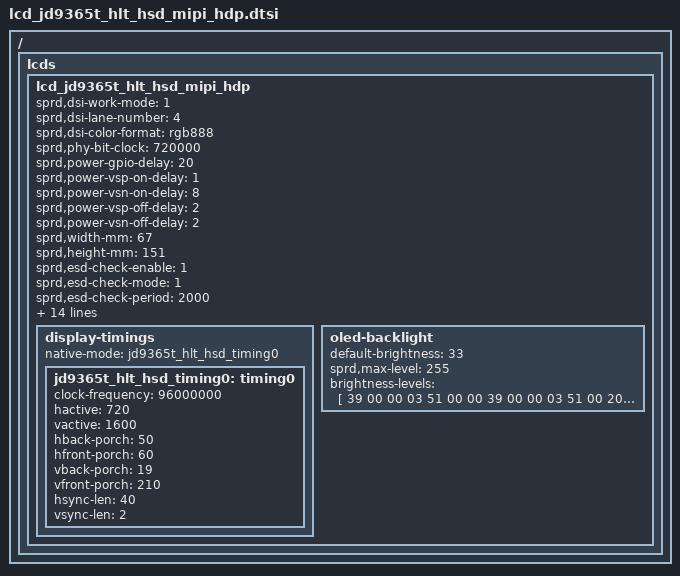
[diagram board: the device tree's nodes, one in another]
/*
 * jd9365t  LCD config dtsi file for spreadtrum
 *
 * Copyright (C) 2018, Spreadtrum Communications Inc.
 *
 * SPDX-License-Identifier: (GPL-2.0+ OR MIT)
 */

/ {
	fragment {
		target-path = "/";
		__overlay__ {
			lcds {
				lcd_jd9365t_hlt_hsd_mipi_hdp: lcd_jd9365t_hlt_hsd_mipi_hdp {
					sprd,dsi-work-mode = <1>; /* video burst mode*/
					sprd,dsi-lane-number = <4>;
					sprd,dsi-color-format = "rgb888";

					sprd,phy-bit-clock = <720000>; /* kbps */
					//sprd,phy-escape-clock = <20000>;/* kHz */
					//sprd,dpi-clk-div = <1>;
					sprd,power-gpio-delay = <20>;/* ms */
					sprd,power-vsp-on-delay = <1>;
					sprd,power-vsn-on-delay = <8>;
					sprd,power-vsp-off-delay = <2>;
					sprd,power-vsn-off-delay = <2>;

					sprd,width-mm = <67>;
					sprd,height-mm = <151>;

					sprd,esd-check-enable = <1>;
					sprd,esd-check-mode = <1>;
					sprd,esd-check-period = <2000>;

					sprd,reset-on-sequence = <1 5>, <0 10>, <1 10>;
					sprd,reset-off-sequence = <0 5>;

					sprd,ddi-need-tp-reset = <1>;
					sprd,ddi-tp-reset-gpio = <209>;

					sprd,deep-sleep-in = <1>;

					sprd,use-dcs-write;
					sprd,initial-command = [
						39 00 00 04 DF 93 83 16
						39 00 00 02 DE 00
						39 00 00 13 B3 10 80 85 00 FF FF 00 00 00 00 64 64 3C 3C 33 11 50 50
						39 00 00 06 B2 01 23 60 88 24
						39 00 00 04 B6 0C 99 AE
						39 00 00 04 B9 3C 33 35
						39 00 00 08 BB 0C 31 43 64 3C 20 20
						39 00 00 03 BD 00 6C
						39 00 00 06 C0 00 D5 00 D5 00
						39 00 00 2B CB 5E 4D 40 2F 22 1E 11 19 07 27 2B 30 52 42 4D 41 3E 33 23 17 02 5E 4D 40 2F 22 1E 11 19 07 27 2B 30 52 42 4D 41 3E 33 23 17 02
						39 00 00 02 CC 33
						39 00 00 03 CD 10 10
						39 00 00 05 BF 50 32 33 C3
						39 00 00 0E C3 13 00 06 16 9B 00 9D 08 16 04 18 08 16
						39 00 00 0B C5 30 20 87 00 00 00 00 38 00 11
						39 00 00 05 C6 00 B6 D2 14
						39 00 00 11 CE 01 00 00 00 00 00 3C 3C 3C 3C 3C 3C 3C 3C 3C 3C
						39 00 00 11 CF 00 00 00 00 00 00 C0 C0 C0 C0 C0 C0 C0 C0 C0 C0
						39 00 00 1E D0 00 1F 1F 1F 1F 1F 1E 1F 17 18 04 06 08 0A 00 10 1F 1F 1F 1F 1F 1F 1F 00 00 00 03 C0 00
						39 00 00 1E D1 00 1F 1F 1F 1F 1F 1E 1F 17 18 05 07 09 0B 01 11 1F 1F 1F 1F 1F 1F 1F 00 00 00 03 C0 00
						39 00 00 1E D2 00 1F 1F 1F 1F 1F 1F 1E 17 18 0B 09 07 05 11 01 1F 1F 1F 1F 1F 1F 1F 00 00 00 03 C0 00
						39 00 00 1E D3 00 1F 1F 1F 1F 1F 1F 1E 17 18 0A 08 06 04 10 00 1F 1F 1F 1F 1F 1F 1F 00 00 00 03 C0 00
						39 00 00 3F D4 10 00 00 10 00 0D 00 00 00 00 00 03 04 00 10 A6 54 00 04 03 03 00 01 00 04 01 01 11 60 03 00 05 01 01 00 00 04 00 0A 06 61 00 0F 00 00 00 00 00 00 00 00 00 00 00 00 00 00 00 00 81 03 D4
						39 00 00 1C D5 03 10 03 00 01 00 00 00 00 43 00 00 00 07 32 5A 00 4A 3B 00 00 1E 02 73 00 12 00
						39 00 00 14 D7 00 69 79 69 79 69 79 69 79 69 79 2F 79 69 79 69 79 69 79
						39 00 00 02 DE 01
						39 00 00 02 B5 6F
						39 00 00 03 C5 22 12
						39 00 00 08 C6 3F 0C 00 00 01 E0 78
						39 00 00 02 DE 02
						39 00 00 06 B3 20 A0 EA 5F 4B
						39 00 00 09 B7 44 00 88 00 03 00 6E 10
						39 00 00 02 BD 14
						39 00 00 09 C1 00 40 20 00 14 14 14 14
						39 00 00 08 C2 42 70 01 01 E0 73 F8
						39 00 00 07 C3 20 FB 00 A0 20 62
						39 00 00 0B E5 00 E6 E5 02 27 42 27 42 09 00
						39 00 00 04 E6 10 10 BD
						39 00 00 04 EC 01 7F 22
						39 00 00 02 DE 03
						39 00 00 02 D1 00
						39 00 00 02 DE 00
						39 20 00 02 35 00
						39 00 00 03 51 00 00
						39 00 00 02 55 00
						39 03 00 02 53 2C
						FF 00 00 01 00
						05 78 00 01 11
						//Display On
						05 14 00 01 29
						];

					sprd,sleep-in-command = [
						05 02 00 01 00
						39 38 00 01 28
						39 80 00 01 10
						];

					sprd,sleep-out-command = [
						39 78 00 01 11
						39 32 00 01 29
						];

					sprd,deep-sleep-in-command = [
						05 02 00 01 00
						39 38 00 01 28
						39 80 00 01 10
					];

					display-timings {
						native-mode = <&jd9365t_hlt_hsd_timing0>;

						jd9365t_hlt_hsd_timing0: timing0 {
							clock-frequency = <96000000>;
							hactive = <720>;
							vactive = <1600>;
							hback-porch = <50>;
							hfront-porch = <60>;
							vback-porch = <19>;
							vfront-porch = <210>;
							hsync-len = <40>;
							vsync-len = <2>;
						};
					};

					oled-backlight {
						default-brightness = <33>;
						sprd,max-level = <255>;
						brightness-levels = [
							39 00 00 03 51 00 00
							39 00 00 03 51 00 20
							39 00 00 03 51 00 30
							39 00 00 03 51 00 40
							39 00 00 03 51 00 50
							39 00 00 03 51 00 60
							39 00 00 03 51 00 70
							39 00 00 03 51 00 80
							39 00 00 03 51 00 90
							39 00 00 03 51 00 A0
							39 00 00 03 51 00 B0
							39 00 00 03 51 00 C0
							39 00 00 03 51 00 D0
							39 00 00 03 51 00 E0
							39 00 00 03 51 00 F0
							39 00 00 03 51 01 00
							39 00 00 03 51 01 11
							39 00 00 03 51 01 21
							39 00 00 03 51 01 31
							39 00 00 03 51 01 41
							39 00 00 03 51 01 51
							39 00 00 03 51 01 61
							39 00 00 03 51 01 71
							39 00 00 03 51 01 81
							39 00 00 03 51 01 91
							39 00 00 03 51 01 A1
							39 00 00 03 51 01 B1
							39 00 00 03 51 01 C1
							39 00 00 03 51 01 D1
							39 00 00 03 51 01 E1
							39 00 00 03 51 01 F1
							39 00 00 03 51 02 01
							39 00 00 03 51 02 11
							39 00 00 03 51 02 22
							39 00 00 03 51 02 32
							39 00 00 03 51 02 42
							39 00 00 03 51 02 52
							39 00 00 03 51 02 62
							39 00 00 03 51 02 72
							39 00 00 03 51 02 82
							39 00 00 03 51 02 92
							39 00 00 03 51 02 A2
							39 00 00 03 51 02 B2
							39 00 00 03 51 02 C2
							39 00 00 03 51 02 D2
							39 00 00 03 51 02 E2
							39 00 00 03 51 02 F2
							39 00 00 03 51 03 02
							39 00 00 03 51 03 12
							39 00 00 03 51 03 22
							39 00 00 03 51 03 32
							39 00 00 03 51 03 43
							39 00 00 03 51 03 53
							39 00 00 03 51 03 63
							39 00 00 03 51 03 73
							39 00 00 03 51 03 83
							39 00 00 03 51 03 93
							39 00 00 03 51 03 A3
							39 00 00 03 51 03 B3
							39 00 00 03 51 03 C3
							39 00 00 03 51 03 D3
							39 00 00 03 51 03 E3
							39 00 00 03 51 03 F3
							39 00 00 03 51 04 03
							39 00 00 03 51 04 13
							39 00 00 03 51 04 23
							39 00 00 03 51 04 33
							39 00 00 03 51 04 43
							39 00 00 03 51 04 54
							39 00 00 03 51 04 64
							39 00 00 03 51 04 74
							39 00 00 03 51 04 84
							39 00 00 03 51 04 94
							39 00 00 03 51 04 A4
							39 00 00 03 51 04 B4
							39 00 00 03 51 04 C4
							39 00 00 03 51 04 D4
							39 00 00 03 51 04 E4
							39 00 00 03 51 04 F4
							39 00 00 03 51 05 04
							39 00 00 03 51 05 14
							39 00 00 03 51 05 24
							39 00 00 03 51 05 34
							39 00 00 03 51 05 44
							39 00 00 03 51 05 54
							39 00 00 03 51 05 65
							39 00 00 03 51 05 75
							39 00 00 03 51 05 85
							39 00 00 03 51 05 95
							39 00 00 03 51 05 A5
							39 00 00 03 51 05 B5
							39 00 00 03 51 05 C5
							39 00 00 03 51 05 D5
							39 00 00 03 51 05 E5
							39 00 00 03 51 05 F5
							39 00 00 03 51 06 05
							39 00 00 03 51 06 15
							39 00 00 03 51 06 25
							39 00 00 03 51 06 35
							39 00 00 03 51 06 45
							39 00 00 03 51 06 55
							39 00 00 03 51 06 65
							39 00 00 03 51 06 76
							39 00 00 03 51 06 86
							39 00 00 03 51 06 96
							39 00 00 03 51 06 A6
							39 00 00 03 51 06 B6
							39 00 00 03 51 06 C6
							39 00 00 03 51 06 D6
							39 00 00 03 51 06 E6
							39 00 00 03 51 06 F6
							39 00 00 03 51 07 06
							39 00 00 03 51 07 16
							39 00 00 03 51 07 26
							39 00 00 03 51 07 36
							39 00 00 03 51 07 46
							39 00 00 03 51 07 56
							39 00 00 03 51 07 66
							39 00 00 03 51 07 76
							39 00 00 03 51 07 87
							39 00 00 03 51 07 97
							39 00 00 03 51 07 A7
							39 00 00 03 51 07 B7
							39 00 00 03 51 07 C7
							39 00 00 03 51 07 D7
							39 00 00 03 51 07 E7
							39 00 00 03 51 07 F7
							39 00 00 03 51 08 07
							39 00 00 03 51 08 17
							39 00 00 03 51 08 27
							39 00 00 03 51 08 37
							39 00 00 03 51 08 47
							39 00 00 03 51 08 57
							39 00 00 03 51 08 67
							39 00 00 03 51 08 77
							39 00 00 03 51 08 87
							39 00 00 03 51 08 98
							39 00 00 03 51 08 A8
							39 00 00 03 51 08 B8
							39 00 00 03 51 08 C8
							39 00 00 03 51 08 D8
							39 00 00 03 51 08 E8
							39 00 00 03 51 08 F8
							39 00 00 03 51 09 08
							39 00 00 03 51 09 18
							39 00 00 03 51 09 28
							39 00 00 03 51 09 38
							39 00 00 03 51 09 48
							39 00 00 03 51 09 58
							39 00 00 03 51 09 68
							39 00 00 03 51 09 78
							39 00 00 03 51 09 88
							39 00 00 03 51 09 98
							39 00 00 03 51 09 A9
							39 00 00 03 51 09 B9
							39 00 00 03 51 09 C9
							39 00 00 03 51 09 D9
							39 00 00 03 51 09 E9
							39 00 00 03 51 09 F9
							39 00 00 03 51 0A 09
							39 00 00 03 51 0A 19
							39 00 00 03 51 0A 29
							39 00 00 03 51 0A 39
							39 00 00 03 51 0A 49
							39 00 00 03 51 0A 59
							39 00 00 03 51 0A 69
							39 00 00 03 51 0A 79
							39 00 00 03 51 0A 89
							39 00 00 03 51 0A 99
							39 00 00 03 51 0A A9
							39 00 00 03 51 0A BA
							39 00 00 03 51 0A CA
							39 00 00 03 51 0A DA
							39 00 00 03 51 0A EA
							39 00 00 03 51 0A FA
							39 00 00 03 51 0B 0A
							39 00 00 03 51 0B 1A
							39 00 00 03 51 0B 2A
							39 00 00 03 51 0B 3A
							39 00 00 03 51 0B 4A
							39 00 00 03 51 0B 5A
							39 00 00 03 51 0B 6A
							39 00 00 03 51 0B 7A
							39 00 00 03 51 0B 8A
							39 00 00 03 51 0B 9A
							39 00 00 03 51 0B AA
							39 00 00 03 51 0B BA
							39 00 00 03 51 0B CB
							39 00 00 03 51 0B DB
							39 00 00 03 51 0B EB
							39 00 00 03 51 0B FB
							39 00 00 03 51 0C 0B
							39 00 00 03 51 0C 1B
							39 00 00 03 51 0C 2B
							39 00 00 03 51 0C 3B
							39 00 00 03 51 0C 4B
							39 00 00 03 51 0C 5B
							39 00 00 03 51 0C 6B
							39 00 00 03 51 0C 7B
							39 00 00 03 51 0C 8B
							39 00 00 03 51 0C 9B
							39 00 00 03 51 0C AB
							39 00 00 03 51 0C BB
							39 00 00 03 51 0C CB
							39 00 00 03 51 0C DC
							39 00 00 03 51 0C EC
							39 00 00 03 51 0C FC
							39 00 00 03 51 0D 0C
							39 00 00 03 51 0D 1C
							39 00 00 03 51 0D 2C
							39 00 00 03 51 0D 3C
							39 00 00 03 51 0D 4C
							39 00 00 03 51 0D 5C
							39 00 00 03 51 0D 6C
							39 00 00 03 51 0D 7C
							39 00 00 03 51 0D 8C
							39 00 00 03 51 0D 9C
							39 00 00 03 51 0D AC
							39 00 00 03 51 0D BC
							39 00 00 03 51 0D CC
							39 00 00 03 51 0D DC
							39 00 00 03 51 0D ED
							39 00 00 03 51 0D FD
							39 00 00 03 51 0E 0D
							39 00 00 03 51 0E 1D
							39 00 00 03 51 0E 2D
							39 00 00 03 51 0E 3D
							39 00 00 03 51 0E 4D
							39 00 00 03 51 0E 5D
							39 00 00 03 51 0E 6D
							39 00 00 03 51 0E 7D
							39 00 00 03 51 0E 8D
							39 00 00 03 51 0E 9D
							39 00 00 03 51 0E AD
							39 00 00 03 51 0E BD
							39 00 00 03 51 0E CD
							39 00 00 03 51 0E DD
							39 00 00 03 51 0E ED
							39 00 00 03 51 0E FE
							39 00 00 03 51 0F 0E
							39 00 00 03 51 0F 1E
							39 00 00 03 51 0F 2E
							39 00 00 03 51 0F 3E
							39 00 00 03 51 0F 4E
							39 00 00 03 51 0F 5E
							39 00 00 03 51 0F 6E
							39 00 00 03 51 0F 7E
							39 00 00 03 51 0F 8E
							39 00 00 03 51 0F 9E
							39 00 00 03 51 0F AE
							39 00 00 03 51 0F BE
							39 00 00 03 51 0F CE
							39 00 00 03 51 0F DE
							39 00 00 03 51 0F EE
							39 00 00 03 51 0F FE
							39 00 00 03 51 0F FE
						];
					};
				};
			};
		};
	};
};
